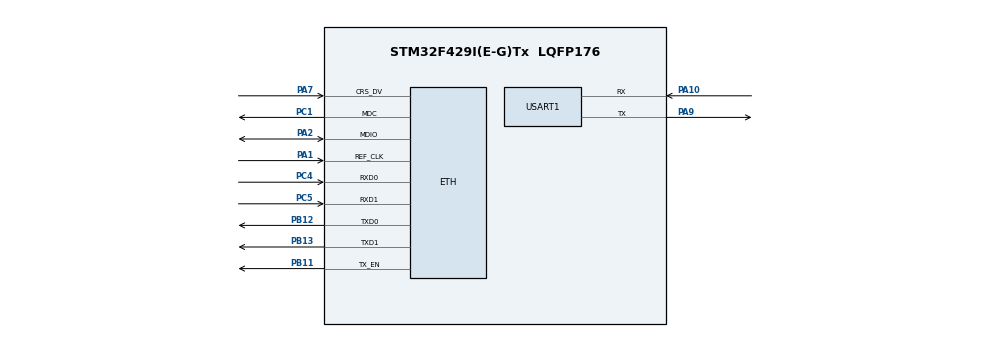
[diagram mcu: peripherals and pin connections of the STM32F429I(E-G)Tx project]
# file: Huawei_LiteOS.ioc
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ETH.MediaInterface=ETH_MEDIA_INTERFACE_RMII
LWIP.Version=v2.0.3_Cube
Mcu.Family=STM32F4
Mcu.Name=STM32F429I(E-G)Tx
Mcu.Package=LQFP176
NVIC.PriorityGroup=NVIC_PRIORITYGROUP_4
PA1.Mode=RMII
PA1.Signal=ETH_REF_CLK
PA10.Mode=Asynchronous
PA10.Signal=USART1_RX
PA2.Mode=RMII
PA2.Signal=ETH_MDIO
PA7.Mode=RMII
PA7.Signal=ETH_CRS_DV
PA9.Mode=Asynchronous
PA9.Signal=USART1_TX
PB11.Mode=RMII
PB11.Signal=ETH_TX_EN
PB12.Mode=RMII
PB12.Signal=ETH_TXD0
PB13.Mode=RMII
PB13.Signal=ETH_TXD1
PC1.Mode=RMII
PC1.Signal=ETH_MDC
PC4.Mode=RMII
PC4.Signal=ETH_RXD0
PC5.Mode=RMII
PC5.Signal=ETH_RXD1
ProjectManager.HeapSize=0x200
ProjectManager.StackSize=0x400
ProjectManager.TargetToolchain=MDK-ARM V5
RCC.48MHZClocksFreq_Value=90000000
RCC.AHBFreq_Value=180000000
RCC.APB1CLKDivider=RCC_HCLK_DIV4
RCC.APB1Freq_Value=45000000
RCC.APB1TimFreq_Value=90000000
RCC.APB2CLKDivider=RCC_HCLK_DIV2
RCC.APB2Freq_Value=90000000
RCC.APB2TimFreq_Value=180000000
RCC.CortexFreq_Value=180000000
RCC.HCLKFreq_Value=180000000
RCC.HSE_VALUE=25000000
RCC.HSI_VALUE=16000000
RCC.LSE_VALUE=32768
RCC.PLLM=8
RCC.PLLN=180
RCC.SYSCLKFreq_VALUE=180000000
RCC.SYSCLKSource=RCC_SYSCLKSOURCE_PLLCLK
RCC.VCOOutputFreq_Value=360000000
USART1.VirtualMode=VM_ASYNC
VP_LWIP_VS_Enabled.Mode=Enabled
board=Huawei_LiteOS

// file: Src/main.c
/**
  ******************************************************************************
  * @file           : main.c
  * @brief          : Main program body
  ******************************************************************************
  * This notice applies to any and all portions of this file
  * that are not between comment pairs USER CODE BEGIN and
  * USER CODE END. Other portions of this file, whether
  * inserted by the user or by software development tools
  * are owned by their respective copyright owners.
  *
  * Copyright (c) 2018 STMicroelectronics International N.V.
  * All rights reserved.
  *
  * Redistribution and use in source and binary forms, with or without
  * modification, are permitted, provided that the following conditions are met:
  *
  * 1. Redistribution of source code must retain the above copyright notice,
  *    this list of conditions and the following disclaimer.
  * 2. Redistributions in binary form must reproduce the above copyright notice,
  *    this list of conditions and the following disclaimer in the documentation
  *    and/or other materials provided with the distribution.
  * 3. Neither the name of STMicroelectronics nor the names of other
  *    contributors to this software may be used to endorse or promote products
  *    derived from this software without specific written permission.
  * 4. This software, including modifications and/or derivative works of this
  *    software, must execute solely and exclusively on microcontroller or
  *    microprocessor devices manufactured by or for STMicroelectronics.
  * 5. Redistribution and use of this software other than as permitted under
  *    this license is void and will automatically terminate your rights under
  *    this license.
  *
  * THIS SOFTWARE IS PROVIDED BY STMICROELECTRONICS AND CONTRIBUTORS "AS IS"
  * AND ANY EXPRESS, IMPLIED OR STATUTORY WARRANTIES, INCLUDING, BUT NOT
  * LIMITED TO, THE IMPLIED WARRANTIES OF MERCHANTABILITY, FITNESS FOR A
  * PARTICULAR PURPOSE AND NON-INFRINGEMENT OF THIRD PARTY INTELLECTUAL PROPERTY
  * RIGHTS ARE DISCLAIMED TO THE FULLEST EXTENT PERMITTED BY LAW. IN NO EVENT
  * SHALL STMICROELECTRONICS OR CONTRIBUTORS BE LIABLE FOR ANY DIRECT, INDIRECT,
  * INCIDENTAL, SPECIAL, EXEMPLARY, OR CONSEQUENTIAL DAMAGES (INCLUDING, BUT NOT
  * LIMITED TO, PROCUREMENT OF SUBSTITUTE GOODS OR SERVICES; LOSS OF USE, DATA,
  * OR PROFITS; OR BUSINESS INTERRUPTION) HOWEVER CAUSED AND ON ANY THEORY OF
  * LIABILITY, WHETHER IN CONTRACT, STRICT LIABILITY, OR TORT (INCLUDING
  * NEGLIGENCE OR OTHERWISE) ARISING IN ANY WAY OUT OF THE USE OF THIS SOFTWARE,
  * EVEN IF ADVISED OF THE POSSIBILITY OF SUCH DAMAGE.
  *
  ******************************************************************************
  */
#include "main.h"

/* USER CODE BEGIN Includes */
#include "sys_init.h"

/* USER CODE END Includes */

UINT32 g_TskHandle;
VOID Hardware_init(void)
{
    HAL_Init();
    SystemClock_Config();
    MX_GPIO_Init();
    MX_USART1_UART_Init();
    MX_LWIP_Init();

}

VOID main_task(void)
{

    while (1)
    {

    }
}

UINT32 create_main_task()
{
    UINT32 uwRet = LOS_OK;
    TSK_INIT_PARAM_S task_init_param;

    task_init_param.usTaskPrio = 0;
    task_init_param.pcName = "main_task";
    task_init_param.pfnTaskEntry = (TSK_ENTRY_FUNC)main_task;
    task_init_param.uwStackSize = 0x1000;

    uwRet = LOS_TaskCreate(&g_TskHandle, &task_init_param);
    return uwRet;
}

int main(void)
{
    UINT32 uwRet = LOS_OK;
    Hardware_init();

    uwRet = LOS_KernelInit();
    if(uwRet != LOS_OK)
    {
        return LOS_NOK;
    }
    uwRet = create_main_task();
    if(uwRet != LOS_OK)
    {
        return LOS_NOK;
    }

    LOS_Start();
    return 0;
}

/************************ (C) COPYRIGHT STMicroelectronics *****END OF FILE****/
